AUTOSAR XML (schema 4-0-3)
package /ComponentTypes
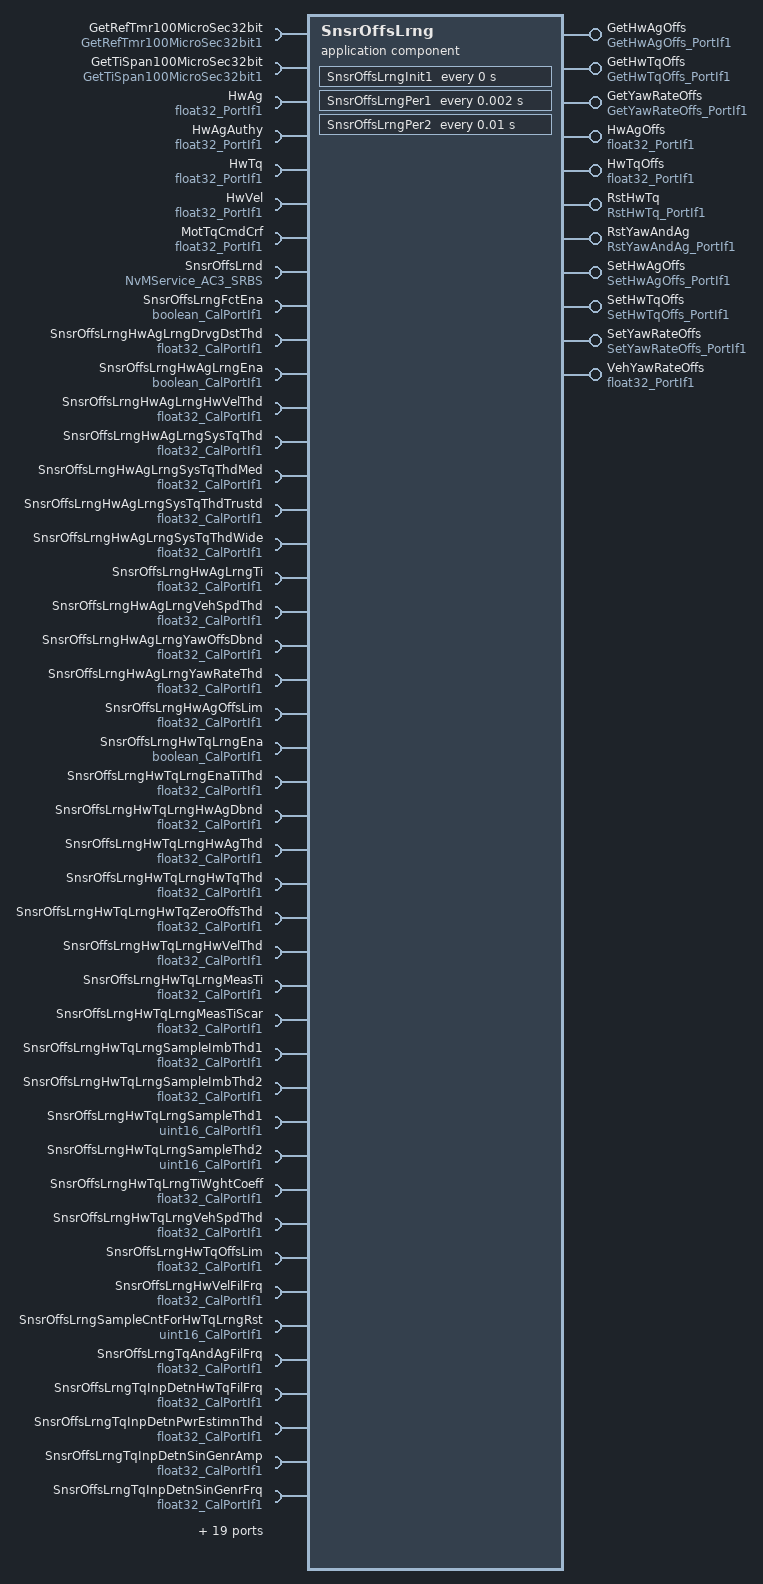
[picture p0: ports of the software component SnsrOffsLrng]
  application sw component type SnsrOffsLrng
    11 x provide port:
      GetHwAgOffs: server-com-spec{operation=Oper, queue-length=1}, provided-interface=GetHwAgOffs_PortIf1
      GetHwTqOffs: server-com-spec{operation=Oper, queue-length=1}, provided-interface=GetHwTqOffs_PortIf1
      GetYawRateOffs: server-com-spec{operation=Oper, queue-length=1}, provided-interface=GetYawRateOffs_PortIf1
      HwAgOffs: nonqueued-sender-com-spec{data-element=Val, init-value=0}, provided-interface=float32_PortIf1
      HwTqOffs: nonqueued-sender-com-spec{data-element=Val, init-value=0}, provided-interface=float32_PortIf1
      RstHwTq: server-com-spec{operation=Oper, queue-length=1}, provided-interface=RstHwTq_PortIf1
      RstYawAndAg: server-com-spec{operation=Oper, queue-length=1}, provided-interface=RstYawAndAg_PortIf1
      SetHwAgOffs: server-com-spec{operation=Oper, queue-length=1}, provided-interface=SetHwAgOffs_PortIf1
      SetHwTqOffs: server-com-spec{operation=Oper, queue-length=1}, provided-interface=SetHwTqOffs_PortIf1
      SetYawRateOffs: server-com-spec{operation=Oper, queue-length=1}, provided-interface=SetYawRateOffs_PortIf1
      VehYawRateOffs: nonqueued-sender-com-spec{data-element=Val, init-value=0}, provided-interface=float32_PortIf1
    63 x require port:
      GetRefTmr100MicroSec32bit: required-interface=GetRefTmr100MicroSec32bit1
      GetTiSpan100MicroSec32bit: required-interface=GetTiSpan100MicroSec32bit1
      HwAg: nonqueued-receiver-com-spec{data-element=Val, filter=data-filter-type=ALWAYS, init-value=0}, required-interface=float32_PortIf1
      HwAgAuthy: nonqueued-receiver-com-spec{data-element=Val, filter=data-filter-type=ALWAYS, init-value=0}, required-interface=float32_PortIf1
      HwTq: nonqueued-receiver-com-spec{data-element=Val, filter=data-filter-type=ALWAYS, init-value=0}, required-interface=float32_PortIf1
      HwVel: nonqueued-receiver-com-spec{data-element=Val, filter=data-filter-type=ALWAYS, init-value=0}, required-interface=float32_PortIf1
      MotTqCmdCrf: nonqueued-receiver-com-spec{data-element=Val, filter=data-filter-type=ALWAYS, init-value=0}, required-interface=float32_PortIf1
      SnsrOffsLrnd: required-interface=NvMService_AC3_SRBS
      SnsrOffsLrngFctEna: parameter-require-com-spec{init-value=0, parameter=Logl}, required-interface=boolean_CalPortIf1
      SnsrOffsLrngHwAgLrngDrvgDstThd: parameter-require-com-spec{init-value=30, parameter=Val}, required-interface=float32_CalPortIf1
      SnsrOffsLrngHwAgLrngEna: parameter-require-com-spec{init-value=0, parameter=Logl}, required-interface=boolean_CalPortIf1
      SnsrOffsLrngHwAgLrngHwVelThd: parameter-require-com-spec{init-value=0.25, parameter=Val}, required-interface=float32_CalPortIf1
      SnsrOffsLrngHwAgLrngSysTqThd: parameter-require-com-spec{init-value=30, parameter=Val}, required-interface=float32_CalPortIf1
      SnsrOffsLrngHwAgLrngSysTqThdMed: parameter-require-com-spec{init-value=3, parameter=Val}, required-interface=float32_CalPortIf1
      SnsrOffsLrngHwAgLrngSysTqThdTrustd: parameter-require-com-spec{init-value=1, parameter=Val}, required-interface=float32_CalPortIf1
      SnsrOffsLrngHwAgLrngSysTqThdWide: parameter-require-com-spec{init-value=20, parameter=Val}, required-interface=float32_CalPortIf1
      SnsrOffsLrngHwAgLrngTi: parameter-require-com-spec{init-value=1000, parameter=Val}, required-interface=float32_CalPortIf1
      SnsrOffsLrngHwAgLrngVehSpdThd: parameter-require-com-spec{init-value=60, parameter=Val}, required-interface=float32_CalPortIf1
      SnsrOffsLrngHwAgLrngYawOffsDbnd: parameter-require-com-spec{init-value=0.1, parameter=Val}, required-interface=float32_CalPortIf1
      SnsrOffsLrngHwAgLrngYawRateThd: parameter-require-com-spec{init-value=0, parameter=Val}, required-interface=float32_CalPortIf1
      SnsrOffsLrngHwAgOffsLim: parameter-require-com-spec{init-value=5, parameter=Val}, required-interface=float32_CalPortIf1
      SnsrOffsLrngHwTqLrngEna: parameter-require-com-spec{init-value=0, parameter=Logl}, required-interface=boolean_CalPortIf1
      SnsrOffsLrngHwTqLrngEnaTiThd: parameter-require-com-spec{init-value=500, parameter=Val}, required-interface=float32_CalPortIf1
      SnsrOffsLrngHwTqLrngHwAgDbnd: parameter-require-com-spec{init-value=0.2, parameter=Val}, required-interface=float32_CalPortIf1
      SnsrOffsLrngHwTqLrngHwAgThd: parameter-require-com-spec{init-value=45, parameter=Val}, required-interface=float32_CalPortIf1
      SnsrOffsLrngHwTqLrngHwTqThd: parameter-require-com-spec{init-value=1.5, parameter=Val}, required-interface=float32_CalPortIf1
      SnsrOffsLrngHwTqLrngHwTqZeroOffsThd: parameter-require-com-spec{init-value=0.15, parameter=Val}, required-interface=float32_CalPortIf1
      SnsrOffsLrngHwTqLrngHwVelThd: parameter-require-com-spec{init-value=0.15, parameter=Val}, required-interface=float32_CalPortIf1
      SnsrOffsLrngHwTqLrngMeasTi: parameter-require-com-spec{init-value=3, parameter=Val}, required-interface=float32_CalPortIf1
      SnsrOffsLrngHwTqLrngMeasTiScar: parameter-require-com-spec{init-value=1, parameter=Val}, required-interface=float32_CalPortIf1
      SnsrOffsLrngHwTqLrngSampleImbThd1: parameter-require-com-spec{init-value=0.6667, parameter=Val}, required-interface=float32_CalPortIf1
      SnsrOffsLrngHwTqLrngSampleImbThd2: parameter-require-com-spec{init-value=0.3334, parameter=Val}, required-interface=float32_CalPortIf1
      SnsrOffsLrngHwTqLrngSampleThd1: parameter-require-com-spec{init-value=20, parameter=Val}, required-interface=uint16_CalPortIf1
      SnsrOffsLrngHwTqLrngSampleThd2: parameter-require-com-spec{init-value=50, parameter=Val}, required-interface=uint16_CalPortIf1
      SnsrOffsLrngHwTqLrngTiWghtCoeff: parameter-require-com-spec{init-value=1, parameter=Val}, required-interface=float32_CalPortIf1
      SnsrOffsLrngHwTqLrngVehSpdThd: parameter-require-com-spec{init-value=0, parameter=Val}, required-interface=float32_CalPortIf1
      SnsrOffsLrngHwTqOffsLim: parameter-require-com-spec{init-value=1.5, parameter=Val}, required-interface=float32_CalPortIf1
      SnsrOffsLrngHwVelFilFrq: parameter-require-com-spec{init-value=250, parameter=Val}, required-interface=float32_CalPortIf1
      SnsrOffsLrngSampleCntForHwTqLrngRst: parameter-require-com-spec{init-value=2000, parameter=Val}, required-interface=uint16_CalPortIf1
      SnsrOffsLrngTqAndAgFilFrq: parameter-require-com-spec{init-value=250, parameter=Val}, required-interface=float32_CalPortIf1
      SnsrOffsLrngTqInpDetnHwTqFilFrq: parameter-require-com-spec{init-value=4, parameter=Val}, required-interface=float32_CalPortIf1
      SnsrOffsLrngTqInpDetnPwrEstimnThd: parameter-require-com-spec{init-value=0, parameter=Val}, required-interface=float32_CalPortIf1
      SnsrOffsLrngTqInpDetnSinGenrAmp: parameter-require-com-spec{init-value=0.1, parameter=Val}, required-interface=float32_CalPortIf1
      SnsrOffsLrngTqInpDetnSinGenrFrq: parameter-require-com-spec{init-value=27.78, parameter=Val}, required-interface=float32_CalPortIf1
      SnsrOffsLrngTqInpDetnStg1FilGain: parameter-require-com-spec{init-value=1.879385242, parameter=Val}, required-interface=float32_CalPortIf1
      SnsrOffsLrngTqInpDetnStg1WinSize: parameter-require-com-spec{init-value=18, parameter=Val}, required-interface=uint8_CalPortIf1
      SnsrOffsLrngTqInpDetnStg2FilGainCen: parameter-require-com-spec{init-value=1.879385242, parameter=Val}, required-interface=float32_CalPortIf1
      SnsrOffsLrngTqInpDetnStg2FilGainDwn: parameter-require-com-spec{init-value=1.891037151, parameter=Val}, required-interface=float32_CalPortIf1
      SnsrOffsLrngTqInpDetnStg2FilGainUp: parameter-require-com-spec{init-value=1.867160853, parameter=Val}, required-interface=float32_CalPortIf1
      SnsrOffsLrngTqInpDetnStg2WinSize: parameter-require-com-spec{init-value=360, parameter=Val}, required-interface=uint16_CalPortIf1
      SnsrOffsLrngYawACdngFilFrq: parameter-require-com-spec{init-value=250, parameter=Val}, required-interface=float32_CalPortIf1
      SnsrOffsLrngYawLrngEna: parameter-require-com-spec{init-value=0, parameter=Logl}, required-interface=boolean_CalPortIf1
      SnsrOffsLrngYawLrngHwAgThd: parameter-require-com-spec{init-value=15, parameter=Val}, required-interface=float32_CalPortIf1
      SnsrOffsLrngYawLrngTi: parameter-require-com-spec{init-value=100, parameter=Val}, required-interface=float32_CalPortIf1
      SnsrOffsLrngYawLrngYawAThd: parameter-require-com-spec{init-value=2, parameter=Val}, required-interface=float32_CalPortIf1
      SnsrOffsLrngYawOffsFrshTiThd: parameter-require-com-spec{init-value=720, parameter=Val}, required-interface=float32_CalPortIf1
      SnsrOffsLrngYawRateCdngFilFrq: parameter-require-com-spec{init-value=250, parameter=Val}, required-interface=float32_CalPortIf1
      SnsrOffsLrngYawRateOffsLim: parameter-require-com-spec{init-value=5, parameter=Val}, required-interface=float32_CalPortIf1
      SysGlbPrmSysTqRat: parameter-require-com-spec{init-value=20, parameter=Val}, required-interface=float32_CalPortIf1
      VehSpd: nonqueued-receiver-com-spec{data-element=Val, filter=data-filter-type=ALWAYS, init-value=0}, required-interface=float32_PortIf1
      VehSpdVld: nonqueued-receiver-com-spec{data-element=Logl, filter=data-filter-type=ALWAYS, init-value=0}, required-interface=boolean_PortIf1
      VehYawRate: nonqueued-receiver-com-spec{data-element=Val, filter=data-filter-type=ALWAYS, init-value=0}, required-interface=float32_PortIf1
      VehYawRateVld: nonqueued-receiver-com-spec{data-element=Logl, filter=data-filter-type=ALWAYS, init-value=0}, required-interface=boolean_PortIf1
    behavior SnsrOffsLrng_InternalBehavior
      ar-typed-per-instance-memorys:
        72 x data, all with sw-calibration-access=READ-ONLY:
          dSnsrOffsLrngHwAgFild: type=float32
          dSnsrOffsLrngHwAgLrngCdnVld: type=boolean
          dSnsrOffsLrngHwAgLrngEna: type=boolean
          dSnsrOffsLrngHwAgLrngRst: type=boolean
          dSnsrOffsLrngHwAgLrngSysTqLoThd: type=float32
          dSnsrOffsLrngHwAgLrngSysTqUpThd: type=float32
          dSnsrOffsLrngHwAgLrngSysTqVldt: type=boolean
          dSnsrOffsLrngHwAgLrngTiVldt: type=boolean
          dSnsrOffsLrngHwTqLrngEna: type=boolean
          dSnsrOffsLrngHwTqLrngEstimnVldt: type=boolean
          dSnsrOffsLrngHwTqLrngHwAgMeas: type=float32
          dSnsrOffsLrngHwTqLrngHwTqMeas: type=float32
          dSnsrOffsLrngHwTqLrngHwTqOffsRaw: type=float32
          dSnsrOffsLrngHwTqLrngMeasEna: type=boolean
          dSnsrOffsLrngHwTqLrngSampleCntTot: type=float32
          dSnsrOffsLrngHwTqLrngSampleImb: type=float32
          dSnsrOffsLrngHwTqLrngTqInpPrsnt: type=boolean
          dSnsrOffsLrngHwTqLrngTqInpPrsntVld: type=boolean
          dSnsrOffsLrngHwVelFild: type=float32
          dSnsrOffsLrngSysTqFild: type=float32
          dSnsrOffsLrngTqInpDetnHwTqFild: type=float32
          dSnsrOffsLrngTqInpDetnStg1Outp: type=float32
          dSnsrOffsLrngTqInpPrsntRaw: type=boolean
          dSnsrOffsLrngYawA: type=float32
          dSnsrOffsLrngYawLrngBiasEstimnRaw: type=float32
          dSnsrOffsLrngYawLrngCdnVld: type=boolean
          dSnsrOffsLrngYawLrngEna: type=boolean
          dSnsrOffsLrngYawRateFild: type=float32
          dSnsrOffsLrngYawRateFildCorrd: type=float32
          HwAgCdngFil: type=FilLpRec1
          HwAgLrngDrvgDstPrev: type=float32
          HwAgLrngFil1: type=FilLpRec1
          HwAgLrngFil2: type=FilLpRec1
          HwAgLrngStRst: type=boolean
          HwAgLrngSysTqFil1: type=FilLpRec1
          HwAgLrngSysTqFil2: type=FilLpRec1
          HwAgMeasFil1: type=FilLpRec1
          HwAgMeasFil2: type=FilLpRec1
          HwTqLrngEnaTmrRef: type=uint32
          HwTqLrngMeasTmrRef: type=uint32
          HwTqLrngStRst: type=boolean
          HwTqLrngTqInpDetnEnaPrev: type=boolean
          HwTqLrngTqInpPrsnt: type=boolean
          HwTqMeasFil1: type=FilLpRec1
          HwTqMeasFil2: type=FilLpRec1
          HwVelCdngFil: type=FilLpRec1
          SnsrOffsLrnd: type=SnsrLrndOffsRec1
          SysTqCdngFil: type=FilLpRec1
          TqInpDetnEnaTi: type=float32
          TqInpDetnHwTqFil: type=FilLpRec1
          TqInpDetnHwTqPreProc: type=float32
          TqInpDetnPreProcEnaLoop: type=uint16
          TqInpDetnSinGenrAg: type=float32
          TqInpDetnStg1Buf: type=Ary1D_f32_72
          TqInpDetnStg1FilSt1: type=float32
          TqInpDetnStg1FilSt2: type=float32
          TqInpDetnStg1Idx: type=uint8
          TqInpDetnStg2CenFilSt1: type=float32
          TqInpDetnStg2CenFilSt2: type=float32
          TqInpDetnStg2DwnFilSt1: type=float32
          TqInpDetnStg2DwnFilSt2: type=float32
          TqInpDetnStg2UpFilSt1: type=float32
          TqInpDetnStg2UpFilSt2: type=float32
          VehYawRateLrngStRst: type=boolean
          VehYawRateOffsFrsh: type=boolean
          YawACdngFil: type=FilLpRec1
          YawCdngFil1: type=FilLpRec1
          YawCdngFil2: type=FilLpRec1
          YawLrngElpdLrngTi: type=float32
          YawLrngFil1: type=FilLpRec1
          YawLrngFil2: type=FilLpRec1
          YawRatePrev: type=float32
      8 x operation invoked event:
        OIT_GetHwAgOffs_Oper_GetHwAgOffs_Oper: start-on-event=GetHwAgOffs_Oper, operation=GetHwAgOffs.Oper
        OIT_GetHwTqOffs_Oper_GetHwTqOffs_Oper: start-on-event=GetHwTqOffs_Oper, operation=GetHwTqOffs.Oper
        OIT_GetYawRateOffs_Oper_GetYawRateOffs_Oper: start-on-event=GetYawRateOffs_Oper, operation=GetYawRateOffs.Oper
        OIT_RstHwTq_Oper_RstHwTq_Oper: start-on-event=RstHwTq_Oper, operation=RstHwTq.Oper
        OIT_RstYawAndAg_Oper_RstYawAndAg_Oper: start-on-event=RstYawAndAg_Oper, operation=RstYawAndAg.Oper
        OIT_SetHwAgOffs_Oper_SetHwAgOffs_Oper: start-on-event=SetHwAgOffs_Oper, operation=SetHwAgOffs.Oper
        OIT_SetHwTqOffs_Oper_SetHwTqOffs_Oper: start-on-event=SetHwTqOffs_Oper, operation=SetHwTqOffs.Oper
        OIT_SetYawRateOffs_Oper_SetYawRateOffs_Oper: start-on-event=SetYawRateOffs_Oper, operation=SetYawRateOffs.Oper
      timing event SnsrOffsLrng_InitEvent: start-on-event=SnsrOffsLrngInit1, period=0
      timing event TMT_SnsrOffsLrngPer1: start-on-event=SnsrOffsLrngPer1, period=0.002
      timing event TMT_SnsrOffsLrngPer2: start-on-event=SnsrOffsLrngPer2, period=0.01
      explicit-inter-runnable-variables:
        data HwTqLrngSts: type=uint8, init-value=0
      11 x runnable:
        GetHwAgOffs_Oper
        GetHwTqOffs_Oper
        GetYawRateOffs_Oper
        RstHwTq_Oper
          sync call SC_GetRefTmr100MicroSec32bit_Oper: operation=GetRefTmr100MicroSec32bit.Oper, timeout=0
          sync call SC_SnsrOffsLrnd_SetRamBlockStatus: operation=SnsrOffsLrnd.SetRamBlockStatus, timeout=0
        RstYawAndAg_Oper
          sync call SC_SnsrOffsLrnd_SetRamBlockStatus: operation=SnsrOffsLrnd.SetRamBlockStatus, timeout=0
        SetHwAgOffs_Oper
          sync call SC_SnsrOffsLrnd_SetRamBlockStatus: operation=SnsrOffsLrnd.SetRamBlockStatus, timeout=0
        SetHwTqOffs_Oper
          sync call SC_GetRefTmr100MicroSec32bit_Oper: operation=GetRefTmr100MicroSec32bit.Oper, timeout=0
          sync call SC_SnsrOffsLrnd_SetRamBlockStatus: operation=SnsrOffsLrnd.SetRamBlockStatus, timeout=0
        SetYawRateOffs_Oper
          sync call SC_SnsrOffsLrnd_SetRamBlockStatus: operation=SnsrOffsLrnd.SetRamBlockStatus, timeout=0
        SnsrOffsLrngInit1
          data-send-points:
            access SEND_HwAgOffs_Val: accessed-variable=HwAgOffs.Val
            access SEND_HwTqOffs_Val: accessed-variable=HwTqOffs.Val
            access SEND_VehYawRateOffs_Val: accessed-variable=VehYawRateOffs.Val
          sync call SC_SnsrOffsLrnd_GetErrorStatus: operation=SnsrOffsLrnd.GetErrorStatus, timeout=0
          sync call SC_SnsrOffsLrnd_SetRamBlockStatus: operation=SnsrOffsLrnd.SetRamBlockStatus, timeout=0
        SnsrOffsLrngPer1
          data-receive-point-by-arguments:
            6 x access:
              REC_HwAg_Val: accessed-variable=HwAg.Val
              REC_HwAgAuthy_Val: accessed-variable=HwAgAuthy.Val
              REC_HwTq_Val: accessed-variable=HwTq.Val
              REC_HwVel_Val: accessed-variable=HwVel.Val
              REC_VehSpd_Val: accessed-variable=VehSpd.Val
              REC_VehSpdVld_Logl: accessed-variable=VehSpdVld.Logl
          sync call SC_GetRefTmr100MicroSec32bit_Oper: operation=GetRefTmr100MicroSec32bit.Oper, timeout=0
          sync call SC_GetTiSpan100MicroSec32bit_Oper: operation=GetTiSpan100MicroSec32bit.Oper, timeout=0
          written-local-variables:
            access WRITE_HwTqLrngSts: accessed-variable=HwTqLrngSts
        SnsrOffsLrngPer2
          data-receive-point-by-arguments:
            9 x access:
              REC_HwAg_Val: accessed-variable=HwAg.Val
              REC_HwAgAuthy_Val: accessed-variable=HwAgAuthy.Val
              REC_HwTq_Val: accessed-variable=HwTq.Val
              REC_HwVel_Val: accessed-variable=HwVel.Val
              REC_MotTqCmdCrf_Val: accessed-variable=MotTqCmdCrf.Val
              REC_VehSpd_Val: accessed-variable=VehSpd.Val
              REC_VehSpdVld_Logl: accessed-variable=VehSpdVld.Logl
              REC_VehYawRate_Val: accessed-variable=VehYawRate.Val
              REC_VehYawRateVld_Logl: accessed-variable=VehYawRateVld.Logl
          read-local-variables:
            access READ_HwTqLrngSts: accessed-variable=HwTqLrngSts
      swc service dependency NvmSnsrOffsLrnd: assigned-datas=role-based-data-assignment={role=ramBlock, used-data-element=SnsrOffsLrnd}
        assigned-ports:
          port-prototype=SnsrOffsLrnd, role=NvMService_AC3_SRBS
          port-prototype=SnsrOffsLrnd, role=NvMService_AC3_SRBS
        service-needs:
          nv block needs NvmSnsrOffsLrnd: n-data-sets=0, readonly=false, reliability=ERROR-DETECTION, resistant-to-changed-sw=true, restore-at-start=true, store-at-shutdown=true, write-only-once=false, writing-frequency=0, writing-priority=LOW
  swc implementation SnsrOffsLrng_Implementation: behavior=SnsrOffsLrng_InternalBehavior
    code-descriptors:
      code Default: artifact-descriptors=autosar-engineering-object={short-label=Default, category=SWSRC}
